VERSION ""

NS_ :

BS_:

BU_: Headless Tractor_Controller

BO_ 2348876545 Trans_Control_1: 8 Headless
 SG_ MP1_Displacement : 0|16@1+ (1,-10000) [-10000|10000] "" Vector__XXX
 SG_ MP2_Displacement : 16|16@1+ (1,-10000) [-10000|10000] "" Vector__XXX

BO_ 2348876289 Test_Stand_Control_1: 8 Headless
 SG_ Swash_Command : 0|16@1+ (1,-10000) [-10000|10000] "" Vector__XXX
 SG_ Pressure_Command : 16|16@1+ (1,0) [0|4000] "" Vector__XXX

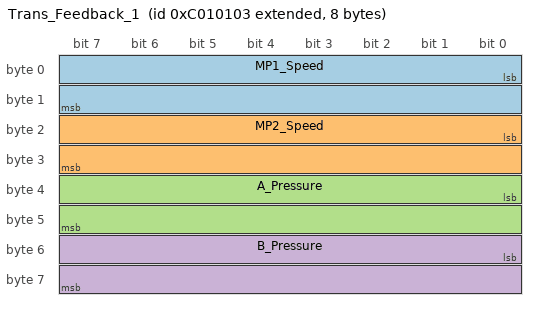
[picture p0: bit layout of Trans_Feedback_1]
BO_ 2348876035 Trans_Feedback_1: 8 Tractor_Controller
 SG_ MP1_Speed : 0|16@1+ (1,0) [0|4500] "" Vector__XXX
 SG_ MP2_Speed : 16|16@1+ (1,0) [0|4500] "" Vector__XXX
 SG_ A_Pressure : 32|16@1+ (1,0) [0|4500] "" Vector__XXX
 SG_ B_Pressure : 48|16@1+ (1,0) [0|4500] "" Vector__XXX

BO_ 2348941571 Trans_Feedback_2: 8 Tractor_Controller
 SG_ MP1_Actual_Displacement : 0|16@1+ (1,-10000) [-10000|10000] "" Vector__XXX
 SG_ MP2_Actual_Displacement : 16|16@1+ (1,-10000) [-10000|10000] "" Vector__XXX
